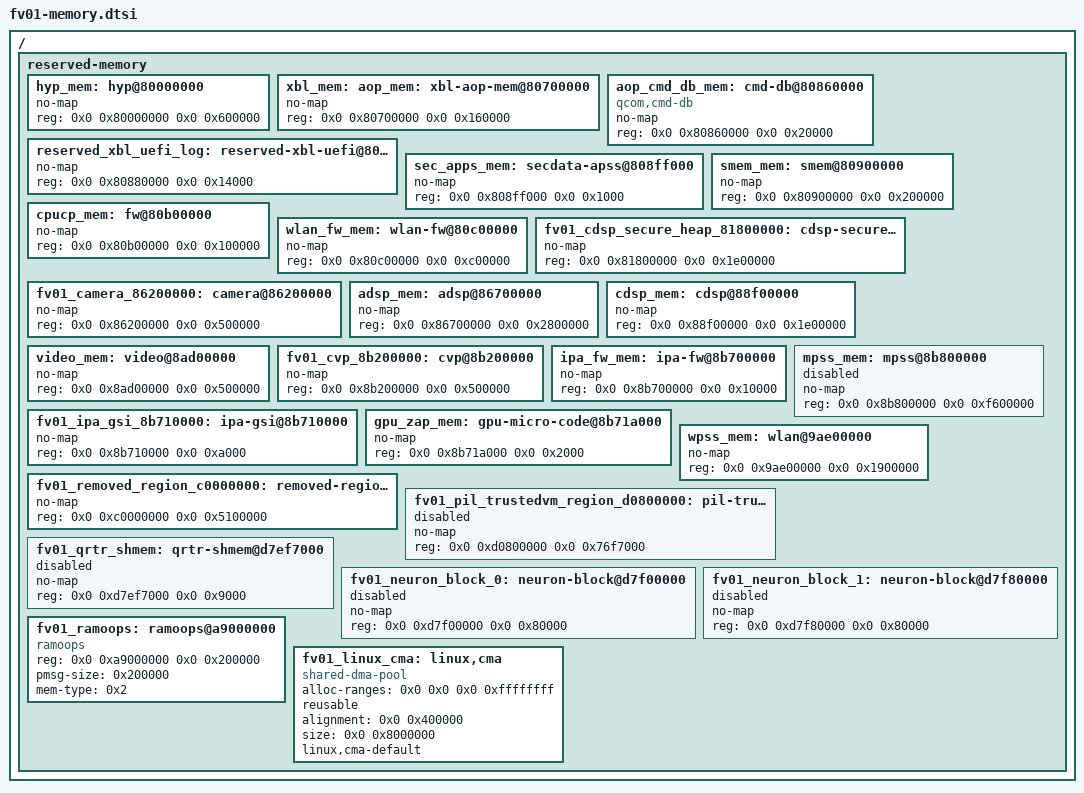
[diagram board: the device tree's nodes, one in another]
// SPDX-License-Identifier: BSD-3-Clause
// FV01 local WIP port, generated from the V02.07 running tree.

// Preserve firmware-owned ranges; consumers must use the labels below.
/delete-node/ &hyp_mem;
/delete-node/ &xbl_mem;
/delete-node/ &aop_mem;
/delete-node/ &aop_cmd_db_mem;
/delete-node/ &reserved_xbl_uefi_log;
/delete-node/ &sec_apps_mem;
/delete-node/ &smem_mem;
/delete-node/ &cpucp_mem;
/delete-node/ &wlan_fw_mem;
/delete-node/ &adsp_mem;
/delete-node/ &video_mem;
/delete-node/ &cdsp_mem;
/delete-node/ &ipa_fw_mem;
/delete-node/ &gpu_zap_mem;
/delete-node/ &mpss_mem;
/delete-node/ &wpss_mem;
/delete-node/ &rmtfs_mem;

/ {
	reserved-memory {
		hyp_mem: hyp@80000000 {
			no-map;
			reg = <0x0 0x80000000 0x0 0x600000>;
		};

		xbl_mem: aop_mem: xbl-aop-mem@80700000 {
			no-map;
			reg = <0x0 0x80700000 0x0 0x160000>;
		};

		aop_cmd_db_mem: cmd-db@80860000 {
			compatible = "qcom,cmd-db";
			no-map;
			reg = <0x0 0x80860000 0x0 0x20000>;
		};

		reserved_xbl_uefi_log: reserved-xbl-uefi@80880000 {
			no-map;
			reg = <0x0 0x80880000 0x0 0x14000>;
		};

		sec_apps_mem: secdata-apss@808ff000 {
			no-map;
			reg = <0x0 0x808ff000 0x0 0x1000>;
		};

		smem_mem: smem@80900000 {
			no-map;
			reg = <0x0 0x80900000 0x0 0x200000>;
		};

		cpucp_mem: fw@80b00000 {
			no-map;
			reg = <0x0 0x80b00000 0x0 0x100000>;
		};

		wlan_fw_mem: wlan-fw@80c00000 {
			no-map;
			reg = <0x0 0x80c00000 0x0 0xc00000>;
		};

		fv01_cdsp_secure_heap_81800000: cdsp-secure-heap@81800000 {
			no-map;
			reg = <0x0 0x81800000 0x0 0x1e00000>;
		};

		fv01_camera_86200000: camera@86200000 {
			no-map;
			reg = <0x0 0x86200000 0x0 0x500000>;
		};

		adsp_mem: adsp@86700000 {
			no-map;
			reg = <0x0 0x86700000 0x0 0x2800000>;
		};

		cdsp_mem: cdsp@88f00000 {
			no-map;
			reg = <0x0 0x88f00000 0x0 0x1e00000>;
		};

		video_mem: video@8ad00000 {
			no-map;
			reg = <0x0 0x8ad00000 0x0 0x500000>;
		};

		fv01_cvp_8b200000: cvp@8b200000 {
			no-map;
			reg = <0x0 0x8b200000 0x0 0x500000>;
		};

		ipa_fw_mem: ipa-fw@8b700000 {
			no-map;
			reg = <0x0 0x8b700000 0x0 0x10000>;
		};

		fv01_ipa_gsi_8b710000: ipa-gsi@8b710000 {
			no-map;
			reg = <0x0 0x8b710000 0x0 0xa000>;
		};

		gpu_zap_mem: gpu-micro-code@8b71a000 {
			no-map;
			reg = <0x0 0x8b71a000 0x0 0x2000>;
		};

		/*
		 * Disabled explicitly (instead of deleting nodes) so U-Boot's
		 * qcom_copy_reserved_memory() sees existing node names and does
		 * not re-inject active no-map carveouts at booti time, returning
		 * 246 MiB (internal MPSS, unused on Wi-Fi/external-WWAN FV01) and
		 * 120 MiB (legacy Android Gunyah TrustedVM) to normal System RAM.
		 */
		mpss_mem: mpss@8b800000 {
			no-map;
			reg = <0x0 0x8b800000 0x0 0xf600000>;
			status = "disabled";
		};

		wpss_mem: wlan@9ae00000 {
			no-map;
			reg = <0x0 0x9ae00000 0x0 0x1900000>;
		};

		fv01_removed_region_c0000000: removed-region@c0000000 {
			no-map;
			reg = <0x0 0xc0000000 0x0 0x5100000>;
		};

		fv01_pil_trustedvm_region_d0800000: pil-trustedvm-region@d0800000 {
			no-map;
			reg = <0x0 0xd0800000 0x0 0x76f7000>;
			status = "disabled";
		};

		fv01_qrtr_shmem: qrtr-shmem@d7ef7000 {
			no-map;
			reg = <0x0 0xd7ef7000 0x0 0x9000>;
			status = "disabled";
		};

		fv01_neuron_block_0: neuron-block@d7f00000 {
			no-map;
			reg = <0x0 0xd7f00000 0x0 0x80000>;
			status = "disabled";
		};

		fv01_neuron_block_1: neuron-block@d7f80000 {
			no-map;
			reg = <0x0 0xd7f80000 0x0 0x80000>;
			status = "disabled";
		};

		fv01_ramoops: ramoops@a9000000 {
			compatible = "ramoops";
			reg = <0x0 0xa9000000 0x0 0x200000>;
			pmsg-size = <0x200000>;
			mem-type = <0x2>;
		};

		/*
		 * Single unified 128 MiB default CMA pool (reusable by apps when idle),
		 * replacing 9 unused Android QSEECOM/display/dump CMA pools that
		 * previously overflowed CONFIG_CMA_AREAS=8.
		 */
		fv01_linux_cma: linux,cma {
			compatible = "shared-dma-pool";
			alloc-ranges = <0x0 0x0 0x0 0xffffffff>;
			reusable;
			alignment = <0x0 0x400000>;
			size = <0x0 0x8000000>;
			linux,cma-default;
		};

	};
};
